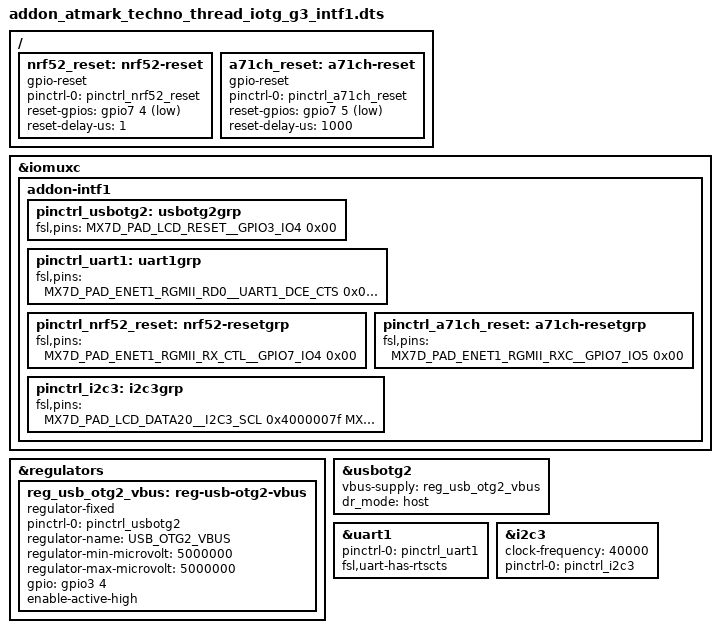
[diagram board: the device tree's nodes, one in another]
/*
 * Copyright (C) 2019 Atmark Techno, Inc. All Rights Reserved.
 * Author: Takumi Ando <takumi.ando@atmark-techno.com>
 *
 * This program is free software; you can redistribute it and/or
 * modify it under the terms of the GNU General Public License
 * version 2 as published by the Free Software Foundation.
 */

#include <dt-bindings/clock/imx7d-clock.h>
#include "../../../../arch/arm/boot/dts/imx7d-pinfunc.h"

/dts-v1/;
/plugin/;
/ {
	fragment@0 {
		target = <&iomuxc>;
		__overlay__ {
			addon-intf1 {
				pinctrl_usbotg2: usbotg2grp {
					fsl,pins = <
						MX7D_PAD_LCD_RESET__GPIO3_IO4 0x00	/* GPIO_AOM1_VBUS_PWREN */
					>;
				};
				pinctrl_uart1: uart1grp {
					fsl,pins = <
						MX7D_PAD_ENET1_RGMII_RD0__UART1_DCE_CTS	0x00	/* INTF1_38 */
						MX7D_PAD_ENET1_RGMII_RD1__UART1_DCE_RTS	0x10	/* INTF1_39 */
						MX7D_PAD_UART1_TX_DATA__UART1_DCE_TX	0x00	/* INTF1_40 */
						MX7D_PAD_UART1_RX_DATA__UART1_DCE_RX	0x70	/* INTF1_41 */
					>;
				};
				pinctrl_nrf52_reset: nrf52-resetgrp {
					fsl,pins = <
						MX7D_PAD_ENET1_RGMII_RX_CTL__GPIO7_IO4	0x00    /* INTF1_42 */
					>;
				};
				pinctrl_a71ch_reset: a71ch-resetgrp {
					fsl,pins = <
						MX7D_PAD_ENET1_RGMII_RXC__GPIO7_IO5	0x00    /* INTF1_43 */
					>;
				};
				pinctrl_i2c3: i2c3grp {
					fsl,pins = <
						MX7D_PAD_LCD_DATA20__I2C3_SCL	0x4000007f	/* INTF1_24 */
						MX7D_PAD_LCD_DATA21__I2C3_SDA	0x4000007f	/* INTF1_25 */
					>;
				};
			};
		};
	};

	fragment@1 {
		target = <&regulators>;
		__overlay__ {
			reg_usb_otg2_vbus: reg-usb-otg2-vbus {
				compatible = "regulator-fixed";
				pinctrl-names = "default";
				pinctrl-0 = <&pinctrl_usbotg2>;
				regulator-name = "USB_OTG2_VBUS";
				regulator-min-microvolt = <5000000>;
				regulator-max-microvolt = <5000000>;
				gpio = <&gpio3 4 0>;
				enable-active-high;
			};
		};
	};

	fragment@2 {
		target = <&usbotg2>;
		__overlay__ {
			vbus-supply = <&reg_usb_otg2_vbus>;
			dr_mode = "host";
			status = "okay";
		};
	};

	fragment@3 {
		target = <&uart1>;
		__overlay__ {
			pinctrl-names = "default";
			pinctrl-0 = <&pinctrl_uart1>;
			fsl,uart-has-rtscts;
			status = "okay";
		};
	};

	fragment@4 {
		target-path = "/";
		__overlay__ {
			nrf52_reset: nrf52-reset {
				compatible = "gpio-reset";
				pinctrl-0 = <&pinctrl_nrf52_reset>;
				reset-gpios = <&gpio7 4 1>;
				reset-delay-us = <1>;
				#reset-cells = <2>;
			};

			a71ch_reset: a71ch-reset {
				compatible = "gpio-reset";
				pinctrl-0 = <&pinctrl_a71ch_reset>;
				reset-gpios = <&gpio7 5 1>;
				reset-delay-us = <1000>;
				#reset-cells = <2>;
			};
		};
	};

	fragment@5 {
		target = <&i2c3>;
		__overlay__ {
			clock-frequency = <40000>;
			pinctrl-names = "default";
			pinctrl-0 = <&pinctrl_i2c3>;
			status = "okay";
		};
	};
};
